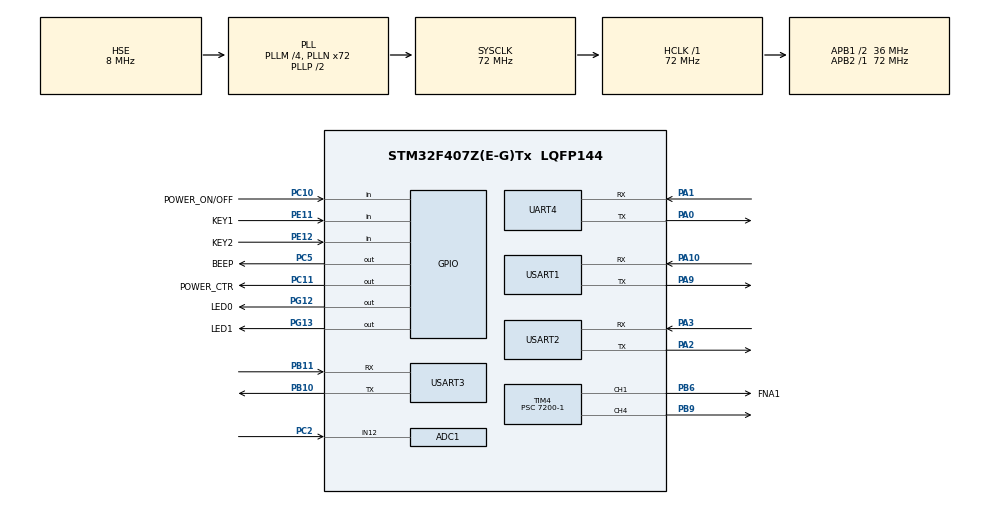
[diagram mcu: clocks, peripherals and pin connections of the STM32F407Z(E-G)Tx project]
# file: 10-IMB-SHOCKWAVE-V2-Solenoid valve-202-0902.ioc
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ADC1.Channel-0\#ChannelRegularConversion=ADC_CHANNEL_12
ADC1.ClockPrescaler=ADC_CLOCK_SYNC_PCLK_DIV6
ADC1.ContinuousConvMode=ENABLE
ADC1.NbrOfConversionFlag=1
ADC1.Rank-0\#ChannelRegularConversion=1
ADC1.SamplingTime-0\#ChannelRegularConversion=ADC_SAMPLETIME_3CYCLES
ADC1.master=1
FREERTOS.Tasks01=PWR_Task,0,128,Start_PWR_Task,Default,NULL,Dynamic,NULL,NULL;KEY_Task,-3,128,Start_KEY_Task,Default,NULL,Dynamic,NULL,NULL;LED_Task,-3,128,Start_LED_Task,Default,NULL,Dynamic,NULL,NULL;FAN_Task,-3,128,Start_FAN_Task,Default,NULL,Dynamic,NULL,NULL;NTC_B3950_Task,-3,128,Start_NTC_B3950_Task,Default,NULL,Dynamic,NULL,NULL;heater_Task,-3,128,Start_heater_Task,Default,NULL,Dynamic,NULL,NULL;Solenoid_adj_Hz,-3,128,Start_Solenoid_adj_Hz,Default,NULL,Dynamic,NULL,NULL
Mcu.Family=STM32F4
Mcu.Name=STM32F407Z(E-G)Tx
Mcu.Package=LQFP144
NVIC.PriorityGroup=NVIC_PRIORITYGROUP_4
NVIC.TIM2_IRQn=true\:5\:0\:true\:false\:true\:true\:true\:true\:true
NVIC.TIM4_IRQn=true\:5\:0\:false\:false\:true\:true\:true\:true\:true
NVIC.TIM7_IRQn=true\:15\:0\:false\:false\:true\:false\:false\:true\:true
NVIC.TimeBase=TIM7_IRQn
NVIC.TimeBaseIP=TIM7
NVIC.USART1_IRQn=true\:5\:0\:false\:false\:true\:true\:true\:true\:true
PA0-WKUP.Mode=Asynchronous
PA0-WKUP.Signal=UART4_TX
PA1.Mode=Asynchronous
PA1.Signal=UART4_RX
PA10.Mode=Asynchronous
PA10.Signal=USART1_RX
PA13.Mode=Serial_Wire
PA13.Signal=SYS_JTMS-SWDIO
PA14.Mode=Serial_Wire
PA14.Signal=SYS_JTCK-SWCLK
PA2.Mode=Asynchronous
PA2.Signal=USART2_TX
PA3.Mode=Asynchronous
PA3.Signal=USART2_RX
PA9.Mode=Asynchronous
PA9.Signal=USART1_TX
PB10.Mode=Asynchronous
PB10.Signal=USART3_TX
PB11.Mode=Asynchronous
PB11.Signal=USART3_RX
PB6.GPIO_Label=FNA1
PB6.GPIO_PuPd=GPIO_PULLDOWN
PB6.GPIO_Speed=GPIO_SPEED_FREQ_HIGH
PB6.Signal=S_TIM4_CH1
PB9.Signal=S_TIM4_CH4
PC10.GPIO_Label=POWER_ON/OFF
PC10.GPIO_PuPd=GPIO_PULLUP
PC10.Signal=GPIO_Input
PC11.GPIO_Label=POWER_CTR
PC11.GPIO_PuPd=GPIO_PULLDOWN
PC11.GPIO_Speed=GPIO_SPEED_FREQ_HIGH
PC11.Signal=GPIO_Output
PC2.Signal=ADCx_IN12
PC5.GPIO_Label=BEEP
PC5.GPIO_PuPd=GPIO_PULLDOWN
PC5.GPIO_Speed=GPIO_SPEED_FREQ_HIGH
PC5.Signal=GPIO_Output
PE11.GPIO_Label=KEY1
PE11.GPIO_PuPd=GPIO_PULLUP
PE11.Signal=GPIO_Input
PE12.GPIO_Label=KEY2
PE12.GPIO_PuPd=GPIO_PULLUP
PE12.Signal=GPIO_Input
PG12.GPIO_Label=LED0
PG12.GPIO_PuPd=GPIO_PULLUP
PG12.GPIO_Speed=GPIO_SPEED_FREQ_HIGH
PG12.PinState=GPIO_PIN_SET
PG12.Signal=GPIO_Output
PG13.GPIO_Label=LED1
PG13.GPIO_PuPd=GPIO_PULLUP
PG13.GPIO_Speed=GPIO_SPEED_FREQ_HIGH
PG13.PinState=GPIO_PIN_SET
PG13.Signal=GPIO_Output
PH0-OSC_IN.Mode=HSE-External-Oscillator
PH0-OSC_IN.Signal=RCC_OSC_IN
PH1-OSC_OUT.Mode=HSE-External-Oscillator
PH1-OSC_OUT.Signal=RCC_OSC_OUT
ProjectManager.HeapSize=0x200
ProjectManager.StackSize=0x400
ProjectManager.TargetToolchain=MDK-ARM V5.32
RCC.48MHZClocksFreq_Value=36000000
RCC.AHBFreq_Value=72000000
RCC.APB1CLKDivider=RCC_HCLK_DIV2
RCC.APB1Freq_Value=36000000
RCC.APB1TimFreq_Value=72000000
RCC.APB2Freq_Value=72000000
RCC.APB2TimFreq_Value=72000000
RCC.CortexFreq_Value=72000000
RCC.HCLKFreq_Value=72000000
RCC.HSE_VALUE=8000000
RCC.HSI_VALUE=16000000
RCC.LSE_VALUE=32768
RCC.PLLM=4
RCC.PLLN=72
RCC.PLLSourceVirtual=RCC_PLLSOURCE_HSE
RCC.SYSCLKFreq_VALUE=72000000
RCC.SYSCLKSource=RCC_SYSCLKSOURCE_PLLCLK
RCC.VCOOutputFreq_Value=144000000
SH.ADCx_IN12.0=ADC1_IN12,IN12
SH.S_TIM4_CH1.0=TIM4_CH1,PWM Generation1 CH1
SH.S_TIM4_CH4.0=TIM4_CH4,PWM Generation4 CH4
TIM2.AutoReloadPreload=TIM_AUTORELOAD_PRELOAD_ENABLE
TIM2.Period=5000-1
TIM2.Prescaler=72-1
TIM4.AutoReloadPreload=TIM_AUTORELOAD_PRELOAD_ENABLE
TIM4.Channel-PWM\ Generation1\ CH1=TIM_CHANNEL_1
TIM4.Channel-PWM\ Generation4\ CH4=TIM_CHANNEL_4
TIM4.Period=10000-1
TIM4.Prescaler=7200-1
UART4.VirtualMode=Asynchronous
USART1.VirtualMode=VM_ASYNC
USART2.VirtualMode=VM_ASYNC
USART3.VirtualMode=VM_ASYNC
VP_FREERTOS_VS_CMSIS_V1.Mode=CMSIS_V1
VP_SYS_VS_tim7.Mode=TIM7
VP_TIM2_VS_ClockSourceINT.Mode=Internal
VP_TIM4_VS_ClockSourceINT.Mode=Internal
board=custom

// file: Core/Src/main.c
/* USER CODE BEGIN Header */
/**
  ******************************************************************************
  * @file           : main.c
  * @brief          : Main program body
  ******************************************************************************
  * @attention
  *
  * Copyright (c) 2024 STMicroelectronics.
  * All rights reserved.
  *
  * This software is licensed under terms that can be found in the LICENSE file
  * in the root directory of this software component.
  * If no LICENSE file comes with this software, it is provided AS-IS.
  *
  ******************************************************************************
  */
/* USER CODE END Header */
#include "main.h"
#include "cmsis_os.h"
#include "adc.h"
#include "tim.h"
#include "usart.h"
#include "gpio.h"

/* USER CODE BEGIN Includes */
#include "PWR_ON.h"

/* USER CODE END Includes */

void SystemClock_Config(void);
void MX_FREERTOS_Init(void);

int main(void)
{

  /* MCU Configuration--------------------------------------------------------*/

  /* Reset of all peripherals, Initializes the Flash interface and the Systick. */
  HAL_Init();

  /* Configure the system clock */
  SystemClock_Config();

  /* Initialize all configured peripherals */
  MX_GPIO_Init();
  MX_UART4_Init();
  MX_USART1_UART_Init();
  MX_USART2_UART_Init();
  MX_USART3_UART_Init();
  MX_TIM4_Init();
  MX_ADC1_Init();
  MX_TIM2_Init();
  /* USER CODE BEGIN 2 */
  PWR_ON();//开机启动和蜂鸣器提示

  /* USER CODE END 2 */

  /* Call init function for freertos objects (in freertos.c) */
  MX_FREERTOS_Init();

  /* Start scheduler */
  osKernelStart();

  /* We should never get here as control is now taken by the scheduler */
  /* Infinite loop */
  while (1)
  {

  }
}

void SystemClock_Config(void)
{
  RCC_OscInitTypeDef RCC_OscInitStruct = {0};
  RCC_ClkInitTypeDef RCC_ClkInitStruct = {0};

  /** Configure the main internal regulator output voltage
  */
  __HAL_RCC_PWR_CLK_ENABLE();
  __HAL_PWR_VOLTAGESCALING_CONFIG(PWR_REGULATOR_VOLTAGE_SCALE1);

  /** Initializes the RCC Oscillators according to the specified parameters
  * in the RCC_OscInitTypeDef structure.
  */
  RCC_OscInitStruct.OscillatorType = RCC_OSCILLATORTYPE_HSE;
  RCC_OscInitStruct.HSEState = RCC_HSE_ON;
  RCC_OscInitStruct.PLL.PLLState = RCC_PLL_ON;
  RCC_OscInitStruct.PLL.PLLSource = RCC_PLLSOURCE_HSE;
  RCC_OscInitStruct.PLL.PLLM = 4;
  RCC_OscInitStruct.PLL.PLLN = 72;
  RCC_OscInitStruct.PLL.PLLP = RCC_PLLP_DIV2;
  RCC_OscInitStruct.PLL.PLLQ = 4;
  if (HAL_RCC_OscConfig(&RCC_OscInitStruct) != HAL_OK)
  {
    Error_Handler();
  }

  /** Initializes the CPU, AHB and APB buses clocks
  */
  RCC_ClkInitStruct.ClockType = RCC_CLOCKTYPE_HCLK|RCC_CLOCKTYPE_SYSCLK
                              |RCC_CLOCKTYPE_PCLK1|RCC_CLOCKTYPE_PCLK2;
  RCC_ClkInitStruct.SYSCLKSource = RCC_SYSCLKSOURCE_PLLCLK;
  RCC_ClkInitStruct.AHBCLKDivider = RCC_SYSCLK_DIV1;
  RCC_ClkInitStruct.APB1CLKDivider = RCC_HCLK_DIV2;
  RCC_ClkInitStruct.APB2CLKDivider = RCC_HCLK_DIV1;

  if (HAL_RCC_ClockConfig(&RCC_ClkInitStruct, FLASH_LATENCY_2) != HAL_OK)
  {
    Error_Handler();
  }
}

void HAL_TIM_PeriodElapsedCallback(TIM_HandleTypeDef *htim)
{
  if (htim->Instance == TIM7) {
    HAL_IncTick();
  }
}

void Error_Handler(void)
{
  __disable_irq();
  while (1)
  {
  }
}

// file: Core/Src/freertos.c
/* USER CODE BEGIN Header */
/**
  ******************************************************************************
  * File Name          : freertos.c
  * Description        : Code for freertos applications
  ******************************************************************************
  * @attention
  *
  * Copyright (c) 2024 STMicroelectronics.
  * All rights reserved.
  *
  * This software is licensed under terms that can be found in the LICENSE file
  * in the root directory of this software component.
  * If no LICENSE file comes with this software, it is provided AS-IS.
  *
  ******************************************************************************
  */
/* USER CODE END Header */

#include "FreeRTOS.h"
#include "task.h"
#include "main.h"
#include "cmsis_os.h"

/* USER CODE BEGIN Includes */
#include "PWR_ON_OFF.h"
#include "tim.h"
#include "Solenoid_adj_Hz.h"
#include "string.h"
#include "stdio.h"

/* USER CODE END Includes */

osThreadId PWR_TaskHandle;
osThreadId KEY_TaskHandle;
osThreadId LED_TaskHandle;
osThreadId FAN_TaskHandle;
osThreadId NTC_B3950_TaskHandle;
osThreadId heater_TaskHandle;
osThreadId Solenoid_adj_HzHandle;

void Start_PWR_Task(void const * argument);
void Start_KEY_Task(void const * argument);
void Start_LED_Task(void const * argument);
void Start_FAN_Task(void const * argument);
void Start_NTC_B3950_Task(void const * argument);
void Start_heater_Task(void const * argument);
void Start_Solenoid_adj_Hz(void const * argument);

void MX_FREERTOS_Init(void); /* (MISRA C 2004 rule 8.1) */

/* GetIdleTaskMemory prototype (linked to static allocation support) */
void vApplicationGetIdleTaskMemory( StaticTask_t **ppxIdleTaskTCBBuffer, StackType_t **ppxIdleTaskStackBuffer, uint32_t *pulIdleTaskStackSize );

/* USER CODE BEGIN GET_IDLE_TASK_MEMORY */
static StaticTask_t xIdleTaskTCBBuffer;
static StackType_t xIdleStack[configMINIMAL_STACK_SIZE];

void vApplicationGetIdleTaskMemory( StaticTask_t **ppxIdleTaskTCBBuffer, StackType_t **ppxIdleTaskStackBuffer, uint32_t *pulIdleTaskStackSize )
{
  *ppxIdleTaskTCBBuffer = &xIdleTaskTCBBuffer;
  *ppxIdleTaskStackBuffer = &xIdleStack[0];
  *pulIdleTaskStackSize = configMINIMAL_STACK_SIZE;
  /* place for user code */
}
/* USER CODE END GET_IDLE_TASK_MEMORY */

void MX_FREERTOS_Init(void) {

  /* Create the thread(s) */
  /* definition and creation of PWR_Task */
  osThreadDef(PWR_Task, Start_PWR_Task, osPriorityNormal, 0, 128);
  PWR_TaskHandle = osThreadCreate(osThread(PWR_Task), NULL);

  /* definition and creation of KEY_Task */
  osThreadDef(KEY_Task, Start_KEY_Task, osPriorityIdle, 0, 128);
  KEY_TaskHandle = osThreadCreate(osThread(KEY_Task), NULL);

  /* definition and creation of LED_Task */
  osThreadDef(LED_Task, Start_LED_Task, osPriorityIdle, 0, 128);
  LED_TaskHandle = osThreadCreate(osThread(LED_Task), NULL);

  /* definition and creation of FAN_Task */
  osThreadDef(FAN_Task, Start_FAN_Task, osPriorityIdle, 0, 128);
  FAN_TaskHandle = osThreadCreate(osThread(FAN_Task), NULL);

  /* definition and creation of NTC_B3950_Task */
  osThreadDef(NTC_B3950_Task, Start_NTC_B3950_Task, osPriorityIdle, 0, 128);
  NTC_B3950_TaskHandle = osThreadCreate(osThread(NTC_B3950_Task), NULL);

  /* definition and creation of heater_Task */
  osThreadDef(heater_Task, Start_heater_Task, osPriorityIdle, 0, 128);
  heater_TaskHandle = osThreadCreate(osThread(heater_Task), NULL);

  /* definition and creation of Solenoid_adj_Hz */
  osThreadDef(Solenoid_adj_Hz, Start_Solenoid_adj_Hz, osPriorityIdle, 0, 128);
  Solenoid_adj_HzHandle = osThreadCreate(osThread(Solenoid_adj_Hz), NULL);

}

void Start_PWR_Task(void const * argument)
{
  /* USER CODE BEGIN Start_PWR_Task */
  /* Infinite loop */
  for(;;)
  {
	  PWR_ON_OFF();//关机操作
      osDelay(20);
  }
  /* USER CODE END Start_PWR_Task */
}

void Start_KEY_Task(void const * argument)
{
  /* USER CODE BEGIN Start_KEY_Task */
  /* Infinite loop */
  for(;;)
  {
	  HAL_GPIO_TogglePin(LED0_GPIO_Port,LED0_Pin);
      osDelay(500);
  }
  /* USER CODE END Start_KEY_Task */
}

void Start_LED_Task(void const * argument)
{
  for(;;)
  {
    osDelay(1);
  }
}

void Start_FAN_Task(void const * argument)
{
  for(;;)
  {
    osDelay(1);
  }
}

void Start_NTC_B3950_Task(void const * argument)
{
  for(;;)
  {
    osDelay(1);
  }
}

void Start_heater_Task(void const * argument)
{
  /* USER CODE BEGIN Start_heater_Task */
  /* Infinite loop */
  for(;;)
  {
	printf("n的值是：%d\r\n",n);
    osDelay(500);
  }
  /* USER CODE END Start_heater_Task */
}

void Start_Solenoid_adj_Hz(void const * argument)
{
  /* USER CODE BEGIN Start_Solenoid_adj_Hz */
  /* Infinite loop */
  for(;;)
  {
    Solenoid_adj_Hz();
  }
  /* USER CODE END Start_Solenoid_adj_Hz */
}
